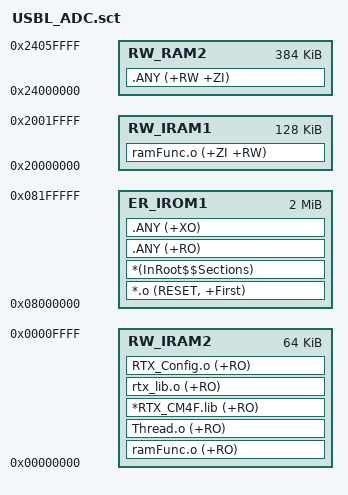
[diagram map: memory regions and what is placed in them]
; *************************************************************
; *** Scatter-Loading Description File generated by uVision ***
; *************************************************************

LR_IROM1 0x08000000 0x00200000  {    ; load region size_region
  ER_IROM1 0x08000000 0x00200000  {  ; load address = execution address
   *.o (RESET, +First)
   *(InRoot$$Sections)
   .ANY (+RO)
   .ANY (+XO)
  }
  RW_RAM2 0x24000000 0x00060000  {  ; RW data
   .ANY (+RW +ZI)
  }
  RW_IRAM1 0x20000000 0x00020000  {
    ramFunc.o (+ZI +RW)
  }
  RW_IRAM2 0x00000000 0x00010000  {
    ramFunc.o (+RO)
    Thread.o (+RO)
   *RTX_CM4F.lib (+RO)
    rtx_lib.o (+RO)
    RTX_Config.o (+RO)
  }
}

